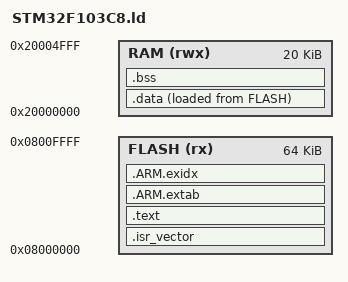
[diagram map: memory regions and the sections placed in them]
/* STM32F103C8T6: 64 KiB flash, 20 KiB SRAM */
ENTRY(Reset_Handler)

MEMORY
{
    FLASH (rx)  : ORIGIN = 0x08000000, LENGTH = 64K
    RAM   (rwx) : ORIGIN = 0x20000000, LENGTH = 20K
}

_estack = ORIGIN(RAM) + LENGTH(RAM);

SECTIONS
{
    .isr_vector :
    {
        . = ALIGN(4);
        KEEP(*(.isr_vector))
        . = ALIGN(4);
    } > FLASH

    .text :
    {
        . = ALIGN(4);
        *(.text*)
        *(.rodata*)
        *(.glue_7)
        *(.glue_7t)
        . = ALIGN(4);
        _etext = .;
    } > FLASH

    .ARM.extab :
    {
        *(.ARM.extab*)
    } > FLASH

    .ARM.exidx :
    {
        __exidx_start = .;
        *(.ARM.exidx*)
        __exidx_end = .;
    } > FLASH

    _sidata = LOADADDR(.data);

    .data :
    {
        . = ALIGN(4);
        _sdata = .;
        *(.data*)
        . = ALIGN(4);
        _edata = .;
    } > RAM AT > FLASH

    .bss (NOLOAD) :
    {
        . = ALIGN(4);
        _sbss = .;
        *(.bss*)
        *(COMMON)
        . = ALIGN(4);
        _ebss = .;
    } > RAM

    /DISCARD/ :
    {
        *(.comment)
        *(.note*)
    }

    .ARM.attributes 0 : { *(.ARM.attributes) }
}
